# STM32L4x5 register map
File version: 1.8
CPU: CM4 r0p1, little endian, MPU, FPU, 4 interrupt priority bits
Registers are 32-bit, read-write, reset 0x0 unless marked. A register's access mark holds for its fields unless they carry their own. Offsets are from the block's base; [hi:lo] are bit positions; {n}, {i} and the like mark numbered series; 'fields as' and 'values as' point back to an identical list.

## EXTI — External interrupt/event controller
Base 0x40010400
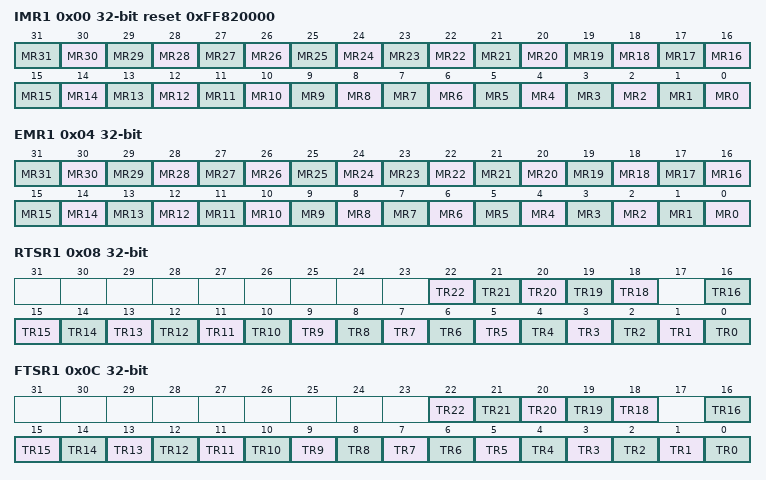
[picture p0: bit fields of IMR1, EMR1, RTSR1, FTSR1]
0x00 IMR1 reset 0xFF820000 — Interrupt mask register
  [all] fields
    0=Masked (Interrupt request line is masked); 1=Unmasked (Interrupt request line is unmasked)
  [n] MR{n} (n=0..31) — Interrupt Mask on line {n}
0x04 EMR1 — Event mask register
  [all] fields
    0=Masked (Event request line is masked); 1=Unmasked (Event request line is unmasked)
  [n] MR{n} (n=0..31) — Event Mask on line {n}
0x08 RTSR1 — Rising Trigger selection register
  [all] fields
    0=Disabled (Rising edge trigger is disabled); 1=Enabled (Rising edge trigger is enabled)
  [n] TR{n} (n=18..22) — Rising trigger event configuration of line {n}
  [n] TR{n} (n=0..16) — Rising trigger event configuration of line {n}
0x0C FTSR1 — Falling Trigger selection register
  [all] fields
    0=Disabled (Falling edge trigger is disabled); 1=Enabled (Falling edge trigger is enabled)
  [n] TR{n} (n=18..22) — Falling trigger event configuration of line {n}
  [n] TR{n} (n=0..16) — Falling trigger event configuration of line {n}
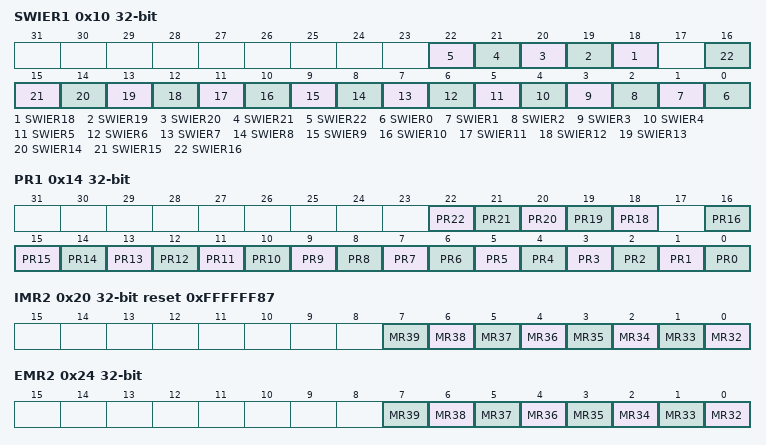
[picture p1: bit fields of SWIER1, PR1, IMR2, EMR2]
0x10 SWIER1 — Software interrupt event register
  [all] fields
    on write: 1=Pend (Generates an interrupt request)
  [n] SWIER{n} (n=18..22) — Software Interrupt on line {n}
  [n] SWIER{n} (n=0..16) — Software Interrupt on line {n}
0x14 PR1 — Pending register
  [all] fields
    on read: 0=NotPending (No trigger request occurred); 1=Pending (Selected trigger request occurred) | on write: 1=Clears pending bit
  [n] PR{n} write-1-clears (n=18..22) — Pending bit {n}
  [n] PR{n} write-1-clears (n=0..16) — Pending bit {n}
0x20 IMR2 reset 0xFFFFFF87 — Interrupt mask register
  [all] fields
    values as the fields of IMR1
  [n-32] MR{n} (n=32..39) — Interrupt Mask on external/internal line {n}
0x24 EMR2 — Event mask register
  [all] fields
    values as the fields of EMR1
  [n-32] MR{n} (n=32..39) — Event mask on external/internal line {n}
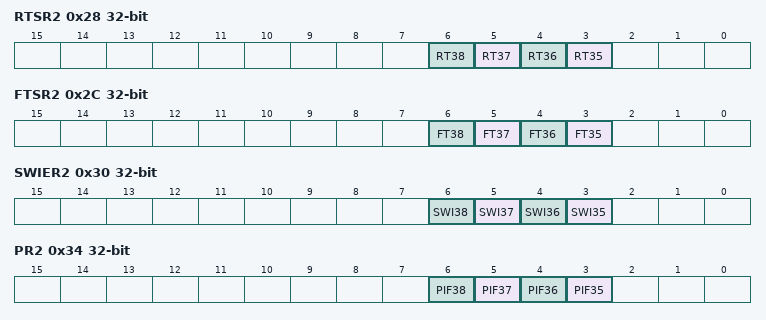
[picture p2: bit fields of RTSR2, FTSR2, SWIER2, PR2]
0x28 RTSR2 — Rising Trigger selection register
  [all] fields
    values as the fields of RTSR1
  [n-32] RT{n} (n=35..38) — Rising trigger event configuration bit of line {n}
0x2C FTSR2 — Falling Trigger selection register
  [all] fields
    values as the fields of FTSR1
  [n-32] FT{n} (n=35..38) — Falling trigger event configuration bit of line {n}
0x30 SWIER2 — Software interrupt event register
  [all] fields
    on write: 1=Pend (Generates an interrupt request)
  [n-32] SWI{n} (n=35..38) — Software interrupt on line {n}
0x34 PR2 — Pending register
  [all] fields
    values as the fields of PR1
  [n-32] PIF{n} write-1-clears (n=35..38) — Pending interrupt flag on line {n}

## VREFBUF — Voltage reference buffer
Base 0x40010030
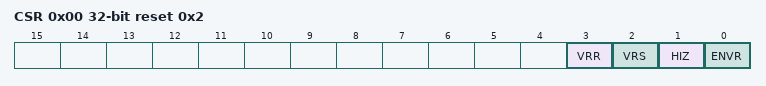
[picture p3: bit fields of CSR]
0x00 CSR access per field reset 0x2 — VREF control and status register
  [3] VRR ro — Voltage reference buffer ready
  [2] VRS rw — Voltage reference scale
  [1] HIZ rw — High impedance mode
  [0] ENVR rw — Voltage reference buffer enable
0x04 CCR — calibration control register
  [5:0] TRIM — Trimming code

## SWPMI1 — Single Wire Protocol Master Interface
Base 0x40008800
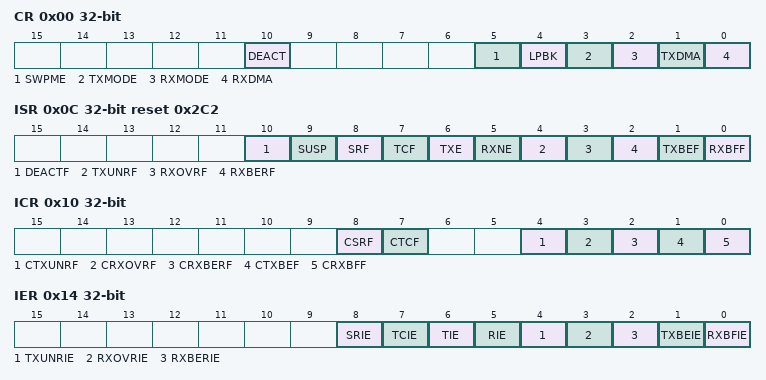
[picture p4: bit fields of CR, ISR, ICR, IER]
0x00 CR — SWPMI Configuration/Control register
  [10] DEACT — Single wire protocol master interface deactivate
  [5] SWPME — Single wire protocol master interface enable
  [4] LPBK — Loopback mode enable
  [3] TXMODE — Transmission buffering mode
  [2] RXMODE — Reception buffering mode
  [1] TXDMA — Transmission DMA enable
  [0] RXDMA — Reception DMA enable
0x04 BRR reset 0x1 — SWPMI Bitrate register
  [5:0] BR — Bitrate prescaler
0x0C ISR ro reset 0x2C2 — SWPMI Interrupt and Status register
  [10] DEACTF — DEACTIVATED flag
  [9] SUSP — SUSPEND flag
  [8] SRF — Slave resume flag
  [7] TCF — Transfer complete flag
  [6] TXE — Transmit data register empty
  [5] RXNE — Receive data register not empty
  [4] TXUNRF — Transmit underrun error flag
  [3] RXOVRF — Receive overrun error flag
  [2] RXBERF — Receive CRC error flag
  [1] TXBEF — Transmit buffer empty flag
  [0] RXBFF — Receive buffer full flag
0x10 ICR wo — SWPMI Interrupt Flag Clear register
  [8] CSRF — Clear slave resume flag
  [7] CTCF — Clear transfer complete flag
  [4] CTXUNRF — Clear transmit underrun error flag
  [3] CRXOVRF — Clear receive overrun error flag
  [2] CRXBERF — Clear receive CRC error flag
  [1] CTXBEF — Clear transmit buffer empty flag
  [0] CRXBFF — Clear receive buffer full flag
0x14 IER — SWPMI Interrupt Enable register
  [8] SRIE — Slave resume interrupt enable
  [7] TCIE — Transmit complete interrupt enable
  [6] TIE — Transmit interrupt enable
  [5] RIE — Receive interrupt enable
  [4] TXUNRIE — Transmit underrun error interrupt enable
  [3] RXOVRIE — Receive overrun error interrupt enable
  [2] RXBERIE — Receive CRC error interrupt enable
  [1] TXBEIE — Transmit buffer empty interrupt enable
  [0] RXBFIE — Receive buffer full interrupt enable
0x18 RFL ro — SWPMI Receive Frame Length register
  [4:0] RFL — Receive frame length
0x1C TDR wo — SWPMI Transmit data register
  [31:0] TD — Transmit data
0x20 RDR ro — SWPMI Receive data register
  [31:0] RD — received data
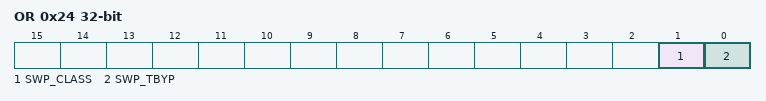
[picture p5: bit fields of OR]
0x24 OR — SWPMI Option register
  [1] SWP_CLASS — SWP class selection
  [0] SWP_TBYP — SWP transceiver bypass
